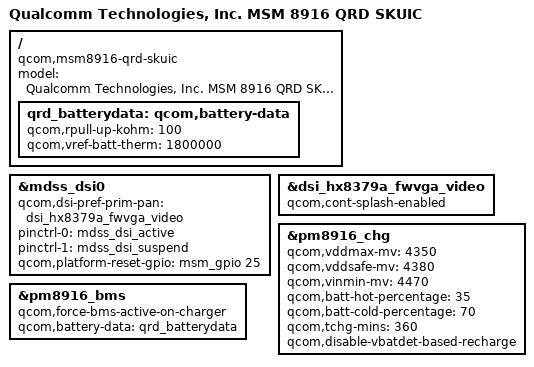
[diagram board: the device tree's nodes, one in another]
/* Copyright (c) 2014, The Linux Foundation. All rights reserved.
 *
 * This program is free software; you can redistribute it and/or modify
 * it under the terms of the GNU General Public License version 2 and
 * only version 2 as published by the Free Software Foundation.
 *
 * This program is distributed in the hope that it will be useful,
 * but WITHOUT ANY WARRANTY; without even the implied warranty of
 * MERCHANTABILITY or FITNESS FOR A PARTICULAR PURPOSE.  See the
 * GNU General Public License for more details.
 */

#include "msm8916-qrd-skui.dtsi"
#include "dsi-panel-hx8379a-fwvga-video.dtsi"

/ {
	model = "Qualcomm Technologies, Inc. MSM 8916 QRD SKUIC";
	compatible = "qcom,msm8916-qrd-skuic", "qcom,msm8916-qrd", "qcom,msm8916", "qcom,qrd";
};

&mdss_dsi0 {
	qcom,dsi-pref-prim-pan = <&dsi_hx8379a_fwvga_video>;
	pinctrl-names = "mdss_default", "mdss_sleep";
	pinctrl-0 = <&mdss_dsi_active>;
	pinctrl-1 = <&mdss_dsi_suspend>;

	qcom,platform-reset-gpio = <&msm_gpio 25 0>;
};

&dsi_hx8379a_fwvga_video {
	qcom,cont-splash-enabled;
};

&pm8916_chg {
	qcom,vddmax-mv = <4350>;
	qcom,vddsafe-mv = <4380>;
	qcom,vinmin-mv = <4470>;
	qcom,batt-hot-percentage = <35>;
	qcom,batt-cold-percentage = <70>;
	qcom,tchg-mins = <360>;
	qcom,disable-vbatdet-based-recharge;
	status = "okay";
};

/ {
	qrd_batterydata: qcom,battery-data {
		qcom,rpull-up-kohm = <100>;
		qcom,vref-batt-therm = <1800000>;

		#include "batterydata-qrd-skuic-4v35-1850mah.dtsi"
	};
};

&pm8916_bms {
	status = "okay";
	qcom,force-bms-active-on-charger;
	qcom,battery-data = <&qrd_batterydata>;
};
